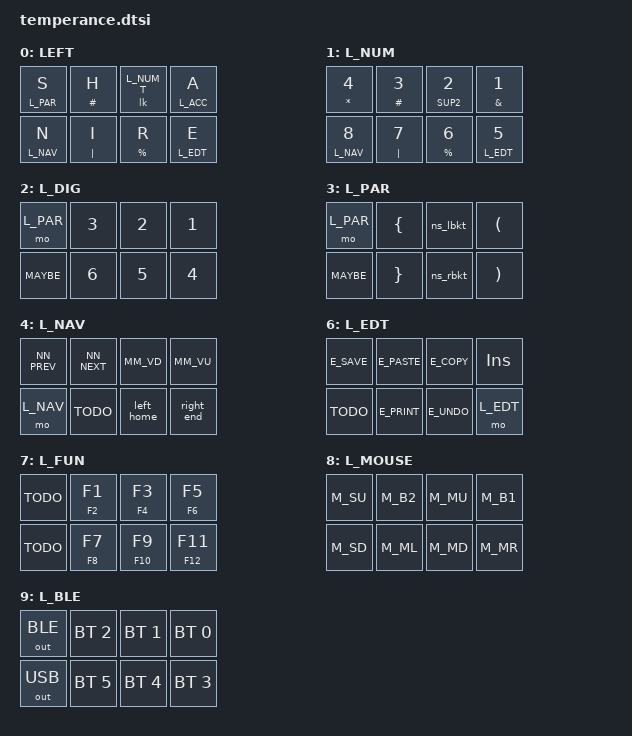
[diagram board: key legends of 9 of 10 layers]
/*
 * Copyright (c) 2024 Petko Yotov pmwiki.org/petko
 *
 * SPDX-License-Identifier: MIT
 */

#define ZMK_POINTING_DEFAULT_MOVE_VAL 600  // default: 600
#define ZMK_POINTING_DEFAULT_SCRL_VAL 6    // default: 10

#include <behaviors.dtsi>
#include <dt-bindings/zmk/keys.h>
#include <dt-bindings/zmk/outputs.h>
#include <dt-bindings/zmk/bt.h>
#include <dt-bindings/zmk/pointing.h>

// HOST_OS: Linux=1, MacOS=2
#define HOST_OS 1
#include "zmk-helpers/helper.h"


// Top row SITA
#define T4 0
#define T3 1
#define T2 2
#define T1 3
// Bottom row NO E
#define B4 4
#define B3 5
#define B2 6
#define B1 7

// #define Z4 8
// #define Z3 9
// #define Z2 10
// #define Z1 11


// The layers need to be numbered in the order they are below,
// starting from zero.
#define L_BASE 0
#define L_NUM  1
#define L_DIG  2
#define L_PAR  3
#define L_NAV  4
#define L_ACC  5
#define L_EDT  6
#define L_FUN  7
#define L_MSE  8
#define L_BLE  9

#define ALL_LEFT L_BASE L_MSE L_BLE L_NUM L_FUN


#include "keyabbrev.dtsi"
#include "characters.dtsi"
#include "timeouts.dtsi"
#include "behaviors.dtsi"
#include "combos.dtsi"


// TODO: keymap for see keys marked TODO and MAYBE 
//    HOLD: J, K, Y, Z, YEN
//    MEH key
//    Layers: Hold-S, Hold-A (accents can be removed)


// #define NONE4 &none &none &none &none 
         

/ { keymap { compatible = "zmk,keymap";
  left {
    display-name = "LEFT";
    // tap-dance doesn't work with layer-hold
    // unless we use non-momentary layers?
    bindings = <
      &lt L_PAR S  &mt HASH H  &lk L_NUM T  &lt L_ACC A
      &lt L_NAV N  &mt PIPE I  &mt PRCNT R  &lt L_EDT E
    >;
  };
  numbers {
    display-name = "L_NUM";
    bindings = <
//       TODO          &kp N3        &mt SUP2  N2  &mt DOT   N1
//       &lt L_NAV N0  &lt L_PAR N6  &mt SPACE N5  &lt L_EDT N4 
      &mt STAR  N4   &mt HASH N3   &mt SUP2  N2   &mt AMPS  N1
      &lt L_NAV N8   &mt PIPE N7   &mt PRCNT N6   &lt L_EDT N5
    >;
  };
  digits {
    display-name = "L_DIG";
    bindings = <
//       &mo L_PAR  P_BRACES  rl_bkt  P_PARENS
      &mo L_PAR  &kp N3  &kp N2   &kp N1
      MAYBE      &kp N6  &kp N5   &kp N4
    >;
  };

  parentheses {
    display-name = "L_PAR";
    bindings = <
//       &mo L_PAR  P_BRACES  rl_bkt  P_PARENS
      &mo L_PAR  &kp LBRC  &ns_lbkt  &kp LPAR
      MAYBE      &kp RBRC  &ns_rbkt  &kp RPAR
    >;
  };

  
  navmedia {
    display-name = "L_NAV";
    bindings = <
      NN_PREV    NN_NEXT    MM_VD       MM_VU   
      &mo L_NAV  TODO       &left_home  &right_end
    >;
  };
  accents {
    display-name = "L_ACC";
    bindings = <
      &mt RBRC LBRC     rbkt_lbkt     &mt RPAR LPAR   &mo L_ACC
      &mt TILDE D_TLD   &ns_dacute    grave_dgrave    MAYBE
    >; 

  };
  editing {
    display-name = "L_EDT";
    bindings = <
      E_SAVE   E_PASTE   E_COPY   &kp INS
      TODO     E_PRINT   E_UNDO   &mo L_EDT
    >;
  };
  functionkeys {
    display-name = "L_FUN";
    bindings = <
      TODO   &mt F2 F1   &mt F4  F3   &mt F6  F5
      TODO   &mt F8 F7   &mt F10 F9   &mt F12 F11
    >;
  };
  mouse {
    display-name = "L_MOUSE";
    bindings = <
     M_SU   M_B2   M_MU   M_B1
     M_SD   M_ML   M_MD   M_MR
//      NONE4
     
    >;
  };

  bluetooth {
    display-name = "L_BLE";
    bindings = <
      &out OUT_BLE   &bt BT_SEL 2  &bt BT_SEL 1  &bt BT_SEL 0
      &out OUT_USB   &bt BT_SEL 5  &bt BT_SEL 4  &bt BT_SEL 3
    >;
  };


}; };


